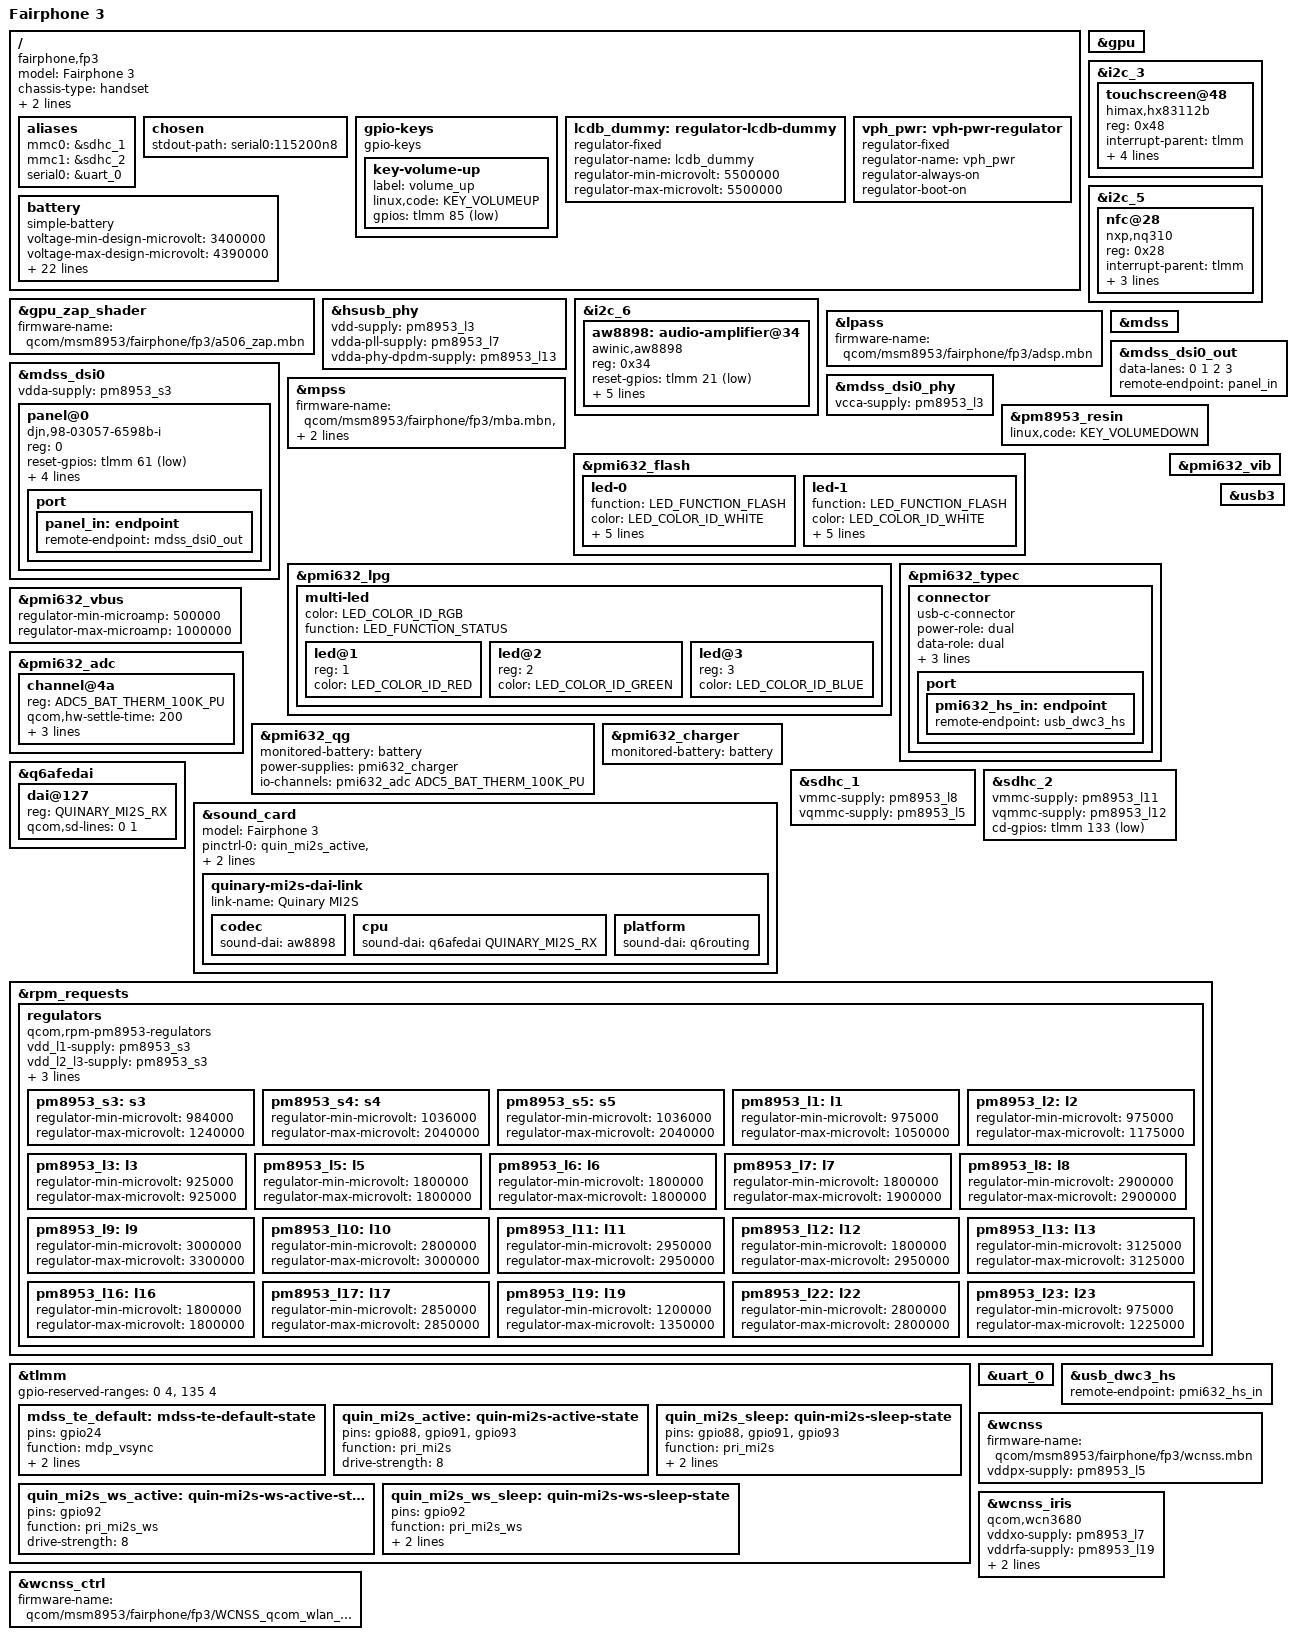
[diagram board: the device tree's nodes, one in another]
// SPDX-License-Identifier: BSD-3-Clause
/*
 * Copyright (c) 2022, Luca Weiss <luca@z3ntu.xyz>
 */
/dts-v1/;

#include <dt-bindings/leds/common.h>
#include "sdm632.dtsi"
#include "pm8953.dtsi"
#include "pmi632.dtsi"

/ {
	model = "Fairphone 3";
	compatible = "fairphone,fp3", "qcom,sdm632";
	chassis-type = "handset";
	qcom,msm-id = <349 0>;
	qcom,board-id = <8 0x10000>;

	aliases {
		mmc0 = &sdhc_1;
		mmc1 = &sdhc_2;
		serial0 = &uart_0;
	};

	chosen {
		stdout-path = "serial0:115200n8";
	};

	gpio-keys {
		compatible = "gpio-keys";

		key-volume-up {
			label = "volume_up";
			linux,code = <KEY_VOLUMEUP>;
			gpios = <&tlmm 85 GPIO_ACTIVE_LOW>;
		};
	};

	/* Dummy regulator until PMI632 has LCDB VSP/VSN support */
	lcdb_dummy: regulator-lcdb-dummy {
		compatible = "regulator-fixed";
		regulator-name = "lcdb_dummy";
		regulator-min-microvolt = <5500000>;
		regulator-max-microvolt = <5500000>;
	};

	vph_pwr: vph-pwr-regulator {
		compatible = "regulator-fixed";
		regulator-name = "vph_pwr";
		regulator-always-on;
		regulator-boot-on;
	};

	battery: battery {
		compatible = "simple-battery";
		voltage-min-design-microvolt = <3400000>;
		voltage-max-design-microvolt = <4390000>;
		energy-full-design-microwatt-hours = <11400000>;
		charge-full-design-microamp-hours = <3000000>;

		ocv-capacity-celsius = <25>;
		ocv-capacity-table-0 = <4370000 100>, <4337400 98>, <4307400 96>,
			<4280600 94>, <4256600 92>, <4233100 90>, <4209700 88>,
			<4186700 86>, <4164000 84>, <4141700 82>, <4120000 80>,
			<4099000 78>, <4078600 76>, <4058700 74>, <4039300 72>,
			<4021400 70>, <4006000 68>, <3990500 66>, <3971300 64>,
			<3949500 62>, <3927700 60>, <3905200 58>, <3884600 56>,
			<3868200 54>, <3854000 52>, <3841600 50>, <3830500 48>,
			<3820400 46>, <3811100 44>, <3802400 42>, <3795100 40>,
			<3788600 38>, <3783000 36>, <3778200 34>, <3774000 32>,
			<3769900 30>, <3765800 28>, <3761300 26>, <3755300 24>,
			<3748200 22>, <3739400 20>, <3728100 18>, <3715600 16>,
			<3701200 14>, <3686100 12>, <3680100 10>, <3678200 9>,
			<3676900 8>, <3673600 7>, <3667900 6>, <3650200 5>,
			<3610600 4>, <3555200 3>, <3481300 2>, <3374500 1>,
			<3193600 0>;
	};
};

&gpu {
	status = "okay";
};

&gpu_zap_shader {
	firmware-name = "qcom/msm8953/fairphone/fp3/a506_zap.mbn";
};

&hsusb_phy {
	vdd-supply = <&pm8953_l3>;
	vdda-pll-supply = <&pm8953_l7>;
	vdda-phy-dpdm-supply = <&pm8953_l13>;

	status = "okay";
};

&i2c_3 {
	status = "okay";

	touchscreen@48 {
		compatible = "himax,hx83112b";
		reg = <0x48>;
		interrupt-parent = <&tlmm>;
		interrupts = <65 IRQ_TYPE_LEVEL_LOW>;
		touchscreen-size-x = <1080>;
		touchscreen-size-y = <2160>;
		reset-gpios = <&tlmm 64 GPIO_ACTIVE_LOW>;
	};
};

&i2c_5 {
	status = "okay";

	nfc@28 {
		compatible = "nxp,nq310", "nxp,nxp-nci-i2c";
		reg = <0x28>;

		interrupt-parent = <&tlmm>;
		interrupts = <17 IRQ_TYPE_LEVEL_HIGH>;

		enable-gpios = <&tlmm 16 GPIO_ACTIVE_HIGH>;
		firmware-gpios = <&tlmm 62 GPIO_ACTIVE_HIGH>;
	};
};

&i2c_6 {
	status = "okay";

	aw8898: audio-amplifier@34 {
		compatible = "awinic,aw8898";
		reg = <0x34>;

		reset-gpios = <&tlmm 21 GPIO_ACTIVE_LOW>;
		interrupts-extended = <&tlmm 20 IRQ_TYPE_LEVEL_HIGH>;

		dvdd-supply = <&pm8953_l5>;
		vddio-supply = <&pm8953_l5>;
		vdd-supply = <&vph_pwr>;

		#sound-dai-cells = <0>;
	};

	/* Fairphone 3+ only: Speaker amp TAS2557 @ 4c */
};

&lpass {
	firmware-name = "qcom/msm8953/fairphone/fp3/adsp.mbn";

	status = "okay";
};

&mdss {
	status = "okay";
};

&mdss_dsi0 {
	vdda-supply = <&pm8953_s3>;
	status = "okay";

	panel@0 {
		compatible = "djn,98-03057-6598b-i";
		reg = <0>;

		reset-gpios = <&tlmm 61 GPIO_ACTIVE_LOW>;

		iovcc-supply = <&pm8953_l6>;
		vsn-supply = <&lcdb_dummy>;
		vsp-supply = <&lcdb_dummy>;

		pinctrl-0 = <&mdss_te_default>;
		pinctrl-names = "default";

		port {
			panel_in: endpoint {
				remote-endpoint = <&mdss_dsi0_out>;
			};
		};
	};
};

&mdss_dsi0_out {
	data-lanes = <0 1 2 3>;
	remote-endpoint = <&panel_in>;
};

&mdss_dsi0_phy {
	vcca-supply = <&pm8953_l3>;
	status = "okay";
};

&mpss {
	firmware-name = "qcom/msm8953/fairphone/fp3/mba.mbn",
			"qcom/msm8953/fairphone/fp3/modem.mbn";
	pll-supply = <&pm8953_l7>;

	status = "okay";
};

&pm8953_resin {
	linux,code = <KEY_VOLUMEDOWN>;
	status = "okay";
};

&pmi632_flash {
	status = "okay";

	led-0 {
		function = LED_FUNCTION_FLASH;
		color = <LED_COLOR_ID_WHITE>;
		led-sources = <1>;
		led-max-microamp = <300000>;
		flash-max-microamp = <1500000>;
		flash-max-timeout-us = <1280000>;
		function-enumerator = <0>;
	};

	led-1 {
		function = LED_FUNCTION_FLASH;
		color = <LED_COLOR_ID_WHITE>;
		led-sources = <2>;
		led-max-microamp = <300000>;
		flash-max-microamp = <1500000>;
		flash-max-timeout-us = <1280000>;
		function-enumerator = <1>;
	};
};

&pmi632_lpg {
	status = "okay";

	multi-led {
		color = <LED_COLOR_ID_RGB>;
		function = LED_FUNCTION_STATUS;

		#address-cells = <1>;
		#size-cells = <0>;

		led@1 {
			reg = <1>;
			color = <LED_COLOR_ID_RED>;
		};

		led@2 {
			reg = <2>;
			color = <LED_COLOR_ID_GREEN>;
		};

		led@3 {
			reg = <3>;
			color = <LED_COLOR_ID_BLUE>;
		};
	};
};

&pmi632_typec {
	status = "okay";

	connector {
		compatible = "usb-c-connector";

		power-role = "dual";
		data-role = "dual";
		self-powered;

		typec-power-opmode = "default";
		pd-disable;

		port {
			pmi632_hs_in: endpoint {
				remote-endpoint = <&usb_dwc3_hs>;
			};
		};
	};
};

&pmi632_vbus {
	regulator-min-microamp = <500000>;
	regulator-max-microamp = <1000000>;
	status = "okay";
};

&pmi632_vib {
	status = "okay";
};

&pmi632_adc {
	channel@4a {
		reg = <ADC5_BAT_THERM_100K_PU>;
		qcom,hw-settle-time = <200>;
		qcom,pre-scaling = <1 1>;
		qcom,ratiometric;
		label = "batt_therm";
	};
};

&pmi632_qg {
	monitored-battery = <&battery>;
	power-supplies = <&pmi632_charger>;
	io-channels = <&pmi632_adc ADC5_BAT_THERM_100K_PU>;
	io-channel-names = "batt-therm";
	status = "okay";
};

&pmi632_charger {
	monitored-battery = <&battery>;
	status = "okay";
};

&q6afedai {
	dai@127 {
		reg = <QUINARY_MI2S_RX>;
		qcom,sd-lines = <0 1>;
	};
};

&sdhc_1 {
	vmmc-supply = <&pm8953_l8>;
	vqmmc-supply = <&pm8953_l5>;

	status = "okay";
};

&sdhc_2 {
	vmmc-supply = <&pm8953_l11>;
	vqmmc-supply = <&pm8953_l12>;

	cd-gpios = <&tlmm 133 GPIO_ACTIVE_LOW>;

	status = "okay";
};

&sound_card {
	model = "Fairphone 3";

	pinctrl-0 = <&quin_mi2s_active>, <&quin_mi2s_ws_active>;
	pinctrl-1 = <&quin_mi2s_sleep>, <&quin_mi2s_ws_sleep>;
	pinctrl-names = "default",
			"sleep";

	status = "okay";

	/* FP3 does not use the codec on PM8953 */
	/delete-property/ audio-routing;
	/delete-node/ primary-mi2s-dai-link;
	/delete-node/ tertiary-mi2s-dai-link;

	quinary-mi2s-dai-link {
		link-name = "Quinary MI2S";

		codec {
			sound-dai = <&aw8898>;
		};

		cpu {
			sound-dai = <&q6afedai QUINARY_MI2S_RX>;
		};

		platform {
			sound-dai = <&q6routing>;
		};
	};
};

&rpm_requests {
	regulators {
		compatible = "qcom,rpm-pm8953-regulators";

		vdd_l1-supply = <&pm8953_s3>;
		vdd_l2_l3-supply = <&pm8953_s3>;
		vdd_l4_l5_l6_l7_l16_l19-supply = <&pm8953_s4>;
		vdd_l8_l11_l12_l13_l14_l15-supply = <&vph_pwr>;
		vdd_l9_l10_l17_l18_l22-supply = <&vph_pwr>;

		pm8953_s3: s3 {
			regulator-min-microvolt = <984000>;
			regulator-max-microvolt = <1240000>;
		};

		pm8953_s4: s4 {
			regulator-min-microvolt = <1036000>;
			regulator-max-microvolt = <2040000>;
		};

		pm8953_s5: s5 {
			regulator-min-microvolt = <1036000>;
			regulator-max-microvolt = <2040000>;
		};

		pm8953_l1: l1 {
			regulator-min-microvolt = <975000>;
			regulator-max-microvolt = <1050000>;
		};

		pm8953_l2: l2 {
			regulator-min-microvolt = <975000>;
			regulator-max-microvolt = <1175000>;
		};

		pm8953_l3: l3 {
			regulator-min-microvolt = <925000>;
			regulator-max-microvolt = <925000>;
		};

		pm8953_l5: l5 {
			regulator-min-microvolt = <1800000>;
			regulator-max-microvolt = <1800000>;
		};

		pm8953_l6: l6 {
			regulator-min-microvolt = <1800000>;
			regulator-max-microvolt = <1800000>;
		};

		pm8953_l7: l7 {
			regulator-min-microvolt = <1800000>;
			regulator-max-microvolt = <1900000>;
		};

		pm8953_l8: l8 {
			regulator-min-microvolt = <2900000>;
			regulator-max-microvolt = <2900000>;
		};

		pm8953_l9: l9 {
			regulator-min-microvolt = <3000000>;
			regulator-max-microvolt = <3300000>;
		};

		pm8953_l10: l10 {
			regulator-min-microvolt = <2800000>;
			regulator-max-microvolt = <3000000>;
		};

		pm8953_l11: l11 {
			regulator-min-microvolt = <2950000>;
			regulator-max-microvolt = <2950000>;
		};

		pm8953_l12: l12 {
			regulator-min-microvolt = <1800000>;
			regulator-max-microvolt = <2950000>;
		};

		pm8953_l13: l13 {
			regulator-min-microvolt = <3125000>;
			regulator-max-microvolt = <3125000>;
		};

		pm8953_l16: l16 {
			regulator-min-microvolt = <1800000>;
			regulator-max-microvolt = <1800000>;
		};

		pm8953_l17: l17 {
			regulator-min-microvolt = <2850000>;
			regulator-max-microvolt = <2850000>;
		};

		pm8953_l19: l19 {
			regulator-min-microvolt = <1200000>;
			regulator-max-microvolt = <1350000>;
		};

		pm8953_l22: l22 {
			regulator-min-microvolt = <2800000>;
			regulator-max-microvolt = <2800000>;
		};

		pm8953_l23: l23 {
			regulator-min-microvolt = <975000>;
			regulator-max-microvolt = <1225000>;
		};
	};
};

&tlmm {
	/*
	 * 0-3: unused but protected by TZ
	 * 135-138: fingerprint reader (SPI)
	 */
	gpio-reserved-ranges = <0 4>, <135 4>;

	mdss_te_default: mdss-te-default-state {
		pins = "gpio24";
		function = "mdp_vsync";
		drive-strength = <2>;
		bias-pull-down;
	};

	quin_mi2s_active: quin-mi2s-active-state {
		pins = "gpio88", "gpio91", "gpio93";
		function = "pri_mi2s";
		drive-strength = <8>;
	};

	quin_mi2s_sleep: quin-mi2s-sleep-state {
		pins = "gpio88", "gpio91", "gpio93";
		function = "pri_mi2s";
		drive-strength = <2>;
		bias-pull-down;
	};

	quin_mi2s_ws_active: quin-mi2s-ws-active-state {
		pins = "gpio92";
		function = "pri_mi2s_ws";
		drive-strength = <8>;
	};

	quin_mi2s_ws_sleep: quin-mi2s-ws-sleep-state {
		pins = "gpio92";
		function = "pri_mi2s_ws";
		drive-strength = <2>;
		bias-pull-down;
	};
};

&uart_0 {
	status = "okay";
};

&usb3 {
	status = "okay";
};

&usb_dwc3_hs {
	remote-endpoint = <&pmi632_hs_in>;
};

&wcnss {
	firmware-name = "qcom/msm8953/fairphone/fp3/wcnss.mbn";
	vddpx-supply = <&pm8953_l5>;

	status = "okay";
};

&wcnss_ctrl {
	firmware-name = "qcom/msm8953/fairphone/fp3/WCNSS_qcom_wlan_nv.bin";
};

&wcnss_iris {
	compatible = "qcom,wcn3680";

	vddxo-supply = <&pm8953_l7>;
	vddrfa-supply = <&pm8953_l19>;
	vddpa-supply = <&pm8953_l9>;
	vdddig-supply = <&pm8953_l5>;
};
